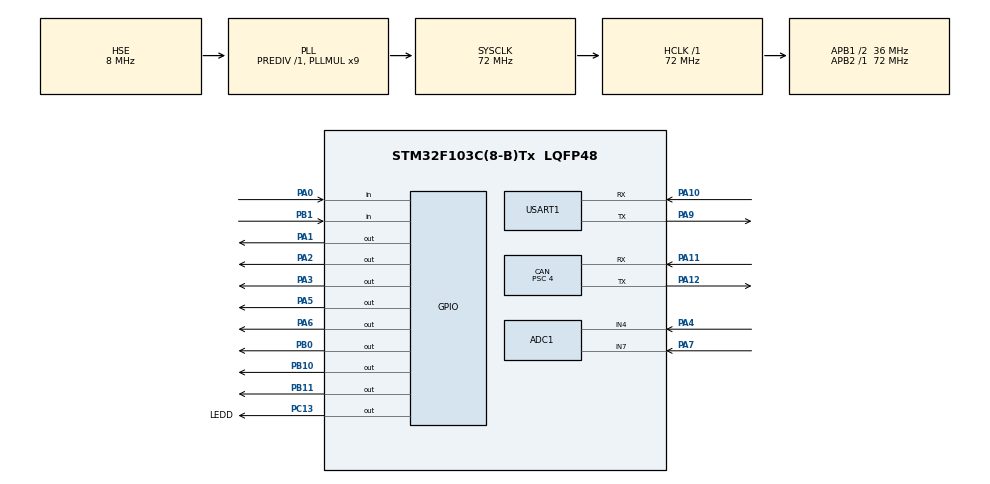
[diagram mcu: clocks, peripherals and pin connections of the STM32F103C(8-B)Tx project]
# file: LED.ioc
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ADC1.Channel-2\#ChannelRegularConversion=ADC_CHANNEL_4
ADC1.Channel-3\#ChannelInjectedConversion=ADC_CHANNEL_4
ADC1.Channel-4\#ChannelRegularConversion=ADC_CHANNEL_7
ADC1.Channel-8\#ChannelInjectedConversion=ADC_CHANNEL_7
ADC1.ContinuousConvMode=ENABLE
ADC1.EnableInjectedConversion=ENABLE
ADC1.InjNumberOfConversion=2
ADC1.InjectedOffset-3\#ChannelInjectedConversion=0
ADC1.InjectedOffset-8\#ChannelInjectedConversion=0
ADC1.InjectedRank-3\#ChannelInjectedConversion=1
ADC1.InjectedRank-8\#ChannelInjectedConversion=2
ADC1.NbrOfConversion=2
ADC1.NbrOfConversionFlag=1
ADC1.Rank-2\#ChannelRegularConversion=1
ADC1.Rank-4\#ChannelRegularConversion=2
ADC1.SamplingTime-2\#ChannelRegularConversion=ADC_SAMPLETIME_239CYCLES_5
ADC1.SamplingTime-3\#ChannelInjectedConversion=ADC_SAMPLETIME_239CYCLES_5
ADC1.SamplingTime-4\#ChannelRegularConversion=ADC_SAMPLETIME_239CYCLES_5
ADC1.SamplingTime-8\#ChannelInjectedConversion=ADC_SAMPLETIME_239CYCLES_5
ADC1.master=1
CAN.BS1=CAN_BS1_5TQ
CAN.BS2=CAN_BS2_3TQ
CAN.CalculateBaudRate=1000000
CAN.CalculateTimeBit=1000
CAN.CalculateTimeQuantum=111.11111111111111
CAN.Prescaler=4
Dma.ADC1.0.Direction=DMA_PERIPH_TO_MEMORY
Dma.ADC1.0.Instance=DMA1_Channel1
Dma.ADC1.0.MemDataAlignment=DMA_MDATAALIGN_HALFWORD
Dma.ADC1.0.MemInc=DMA_MINC_ENABLE
Dma.ADC1.0.Mode=DMA_CIRCULAR
Dma.ADC1.0.PeriphDataAlignment=DMA_PDATAALIGN_HALFWORD
Dma.ADC1.0.PeriphInc=DMA_PINC_DISABLE
Dma.ADC1.0.Priority=DMA_PRIORITY_LOW
Dma.Request0=ADC1
Dma.Request1=USART1_TX
Dma.USART1_TX.1.Direction=DMA_MEMORY_TO_PERIPH
Dma.USART1_TX.1.Instance=DMA1_Channel4
Dma.USART1_TX.1.MemDataAlignment=DMA_MDATAALIGN_BYTE
Dma.USART1_TX.1.MemInc=DMA_MINC_ENABLE
Dma.USART1_TX.1.Mode=DMA_NORMAL
Dma.USART1_TX.1.PeriphDataAlignment=DMA_PDATAALIGN_BYTE
Dma.USART1_TX.1.PeriphInc=DMA_PINC_DISABLE
Dma.USART1_TX.1.Priority=DMA_PRIORITY_LOW
Mcu.Family=STM32F1
Mcu.Name=STM32F103C(8-B)Tx
Mcu.Package=LQFP48
NVIC.ADC1_2_IRQn=true\:0\:0\:true\:false\:true\:true\:true\:true
NVIC.DMA1_Channel1_IRQn=true\:0\:0\:false\:false\:true\:false\:true\:true
NVIC.DMA1_Channel4_IRQn=true\:0\:0\:false\:false\:true\:false\:true\:true
NVIC.PriorityGroup=NVIC_PRIORITYGROUP_4
NVIC.TIM3_IRQn=true\:0\:0\:true\:false\:true\:true\:true\:true
NVIC.USART1_IRQn=true\:0\:0\:true\:false\:true\:true\:true\:true
NVIC.USB_LP_CAN1_RX0_IRQn=true\:0\:0\:false\:false\:true\:true\:true\:true
PA0-WKUP.Signal=GPIO_Input
PA1.Signal=GPIO_Output
PA10.Mode=Asynchronous
PA10.Signal=USART1_RX
PA11.Mode=CAN_Activate
PA11.Signal=CAN_RX
PA12.Mode=CAN_Activate
PA12.Signal=CAN_TX
PA13.Mode=Serial_Wire
PA13.Signal=SYS_JTMS-SWDIO
PA14.Mode=Serial_Wire
PA14.Signal=SYS_JTCK-SWCLK
PA2.Signal=GPIO_Output
PA3.Signal=GPIO_Output
PA4.Signal=ADCx_IN4
PA5.Signal=GPIO_Output
PA6.Signal=GPIO_Output
PA7.Signal=ADCx_IN7
PA9.Mode=Asynchronous
PA9.Signal=USART1_TX
PB0.Signal=GPIO_Output
PB1.Signal=GPIO_Input
PB10.Signal=GPIO_Output
PB11.Signal=GPIO_Output
PC13-TAMPER-RTC.GPIO_Label=LEDD
PC13-TAMPER-RTC.Signal=GPIO_Output
PD0-OSC_IN.Mode=HSE-External-Oscillator
PD0-OSC_IN.Signal=RCC_OSC_IN
PD1-OSC_OUT.Mode=HSE-External-Oscillator
PD1-OSC_OUT.Signal=RCC_OSC_OUT
ProjectManager.HeapSize=0x200
ProjectManager.StackSize=0x400
ProjectManager.TargetToolchain=MDK-ARM V5.32
RCC.ADCPresc=RCC_ADCPCLK2_DIV6
RCC.AHBFreq_Value=72000000
RCC.APB1CLKDivider=RCC_HCLK_DIV2
RCC.APB1Freq_Value=36000000
RCC.APB1TimFreq_Value=72000000
RCC.APB2Freq_Value=72000000
RCC.APB2TimFreq_Value=72000000
RCC.HCLKFreq_Value=72000000
RCC.PLLMUL=RCC_PLL_MUL9
RCC.PLLSourceVirtual=RCC_PLLSOURCE_HSE
RCC.SYSCLKFreq_VALUE=72000000
RCC.SYSCLKSource=RCC_SYSCLKSOURCE_PLLCLK
RCC.USBFreq_Value=72000000
SH.ADCx_IN4.0=ADC1_IN4,IN4
SH.ADCx_IN7.0=ADC1_IN7,IN7
TIM3.Period=999
TIM3.Prescaler=35
USART1.VirtualMode=VM_ASYNC
VP_TIM3_VS_ClockSourceINT.Mode=Internal
board=custom

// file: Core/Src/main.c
/* USER CODE BEGIN Header */
/**
  ******************************************************************************
  * @file           : main.c
  * @brief          : Main program body
  ******************************************************************************
  * @attention
  *
  * Copyright (c) 2022 STMicroelectronics.
  * All rights reserved.
  *
  * This software is licensed under terms that can be found in the LICENSE file
  * in the root directory of this software component.
  * If no LICENSE file comes with this software, it is provided AS-IS.
  *
  ******************************************************************************
  */
/* USER CODE END Header */
#include "main.h"
#include "adc.h"
#include "can.h"
#include "dma.h"
#include "tim.h"
#include "usart.h"
#include "gpio.h"

/* USER CODE BEGIN Includes */
#include "usr.h"
#include "RUI_ANONYMITY.h"
#include "kalman.h"
/* USER CODE END Includes */

void SystemClock_Config(void);

int main(void)
{

  /* MCU Configuration--------------------------------------------------------*/

  /* Reset of all peripherals, Initializes the Flash interface and the Systick. */
  HAL_Init();

  /* Configure the system clock */
  SystemClock_Config();

  /* Initialize all configured peripherals */
  MX_GPIO_Init();
  MX_DMA_Init();
  MX_ADC1_Init();
  MX_USART1_UART_Init();
  MX_TIM3_Init();
  MX_CAN_Init();
  /* USER CODE BEGIN 2 */

  HAL_GPIO_WritePin(GPIOA,GPIO_PIN_6,1);
  HAL_GPIO_WritePin(GPIOB,GPIO_PIN_0,0);

  HAL_GPIO_WritePin(GPIOA,GPIO_PIN_3,1);
  HAL_GPIO_WritePin(GPIOA,GPIO_PIN_5,0);

  HAL_GPIO_WritePin(GPIOA,GPIO_PIN_2,1);
  HAL_GPIO_WritePin(GPIOA,GPIO_PIN_1,0);

  HAL_GPIO_WritePin(GPIOB,GPIO_PIN_11,1);
  HAL_GPIO_WritePin(GPIOB,GPIO_PIN_10,0);

  HAL_TIM_Base_Start_IT(&htim3);
  HAL_ADCEx_Calibration_Start(&hadc1);
  HAL_ADC_Start_DMA(&hadc1,(uint32_t*)&MYADC.ADC_Value,2);

  /* USER CODE END 2 */

  /* Infinite loop */
  while (1)
  {

  }
}

void SystemClock_Config(void)
{
  RCC_OscInitTypeDef RCC_OscInitStruct = {0};
  RCC_ClkInitTypeDef RCC_ClkInitStruct = {0};
  RCC_PeriphCLKInitTypeDef PeriphClkInit = {0};

  /** Initializes the RCC Oscillators according to the specified parameters
  * in the RCC_OscInitTypeDef structure.
  */
  RCC_OscInitStruct.OscillatorType = RCC_OSCILLATORTYPE_HSE;
  RCC_OscInitStruct.HSEState = RCC_HSE_ON;
  RCC_OscInitStruct.HSEPredivValue = RCC_HSE_PREDIV_DIV1;
  RCC_OscInitStruct.HSIState = RCC_HSI_ON;
  RCC_OscInitStruct.PLL.PLLState = RCC_PLL_ON;
  RCC_OscInitStruct.PLL.PLLSource = RCC_PLLSOURCE_HSE;
  RCC_OscInitStruct.PLL.PLLMUL = RCC_PLL_MUL9;
  if (HAL_RCC_OscConfig(&RCC_OscInitStruct) != HAL_OK)
  {
    Error_Handler();
  }

  /** Initializes the CPU, AHB and APB buses clocks
  */
  RCC_ClkInitStruct.ClockType = RCC_CLOCKTYPE_HCLK|RCC_CLOCKTYPE_SYSCLK
                              |RCC_CLOCKTYPE_PCLK1|RCC_CLOCKTYPE_PCLK2;
  RCC_ClkInitStruct.SYSCLKSource = RCC_SYSCLKSOURCE_PLLCLK;
  RCC_ClkInitStruct.AHBCLKDivider = RCC_SYSCLK_DIV1;
  RCC_ClkInitStruct.APB1CLKDivider = RCC_HCLK_DIV2;
  RCC_ClkInitStruct.APB2CLKDivider = RCC_HCLK_DIV1;

  if (HAL_RCC_ClockConfig(&RCC_ClkInitStruct, FLASH_LATENCY_2) != HAL_OK)
  {
    Error_Handler();
  }
  PeriphClkInit.PeriphClockSelection = RCC_PERIPHCLK_ADC;
  PeriphClkInit.AdcClockSelection = RCC_ADCPCLK2_DIV6;
  if (HAL_RCCEx_PeriphCLKConfig(&PeriphClkInit) != HAL_OK)
  {
    Error_Handler();
  }
}

void Error_Handler(void)
{
  __disable_irq();
  while (1)
  {
  }
}
